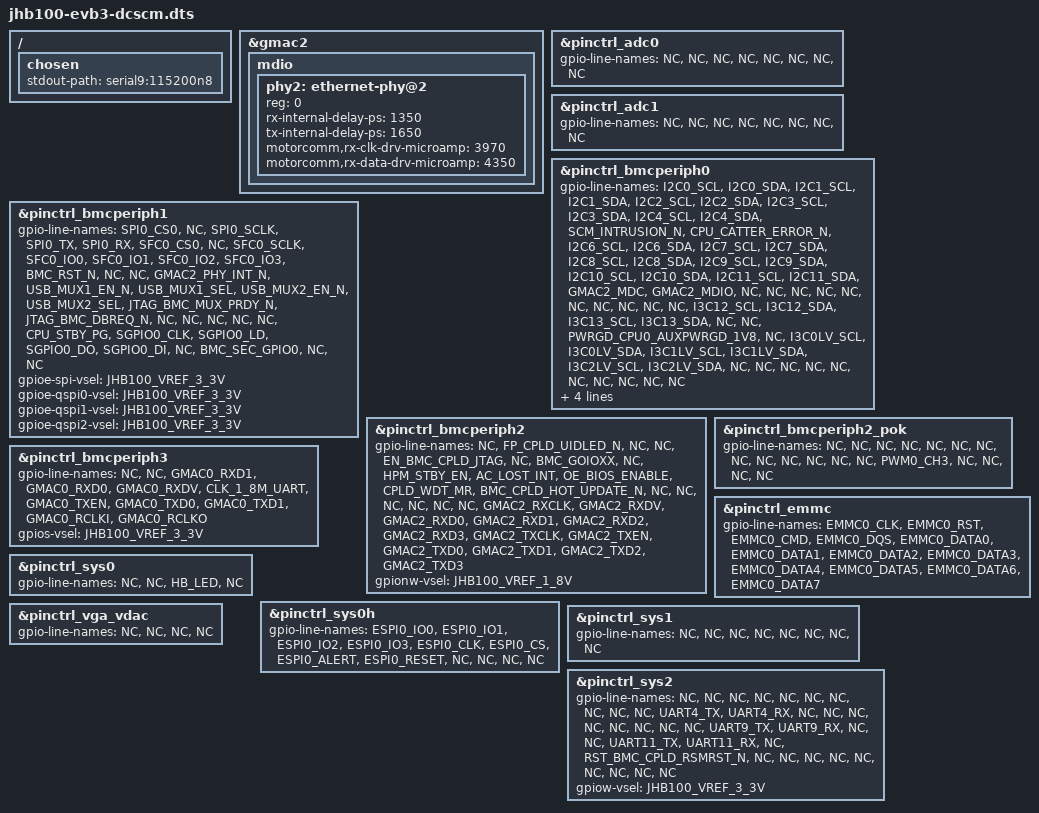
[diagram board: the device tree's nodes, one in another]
// SPDX-License-Identifier: GPL-2.0 OR MIT
/*
 * Copyright (c) 2025 StarFive Technology Co., Ltd.
 */

#include "jhb100-evb3.dtsi"
#include "jhb100-dcscm.dtsi"

/ {
	chosen {
		stdout-path = "serial9:115200n8";
	};
};

&gmac2 {
	mdio {
		phy2: ethernet-phy@2 {
			reg = <0>;
			rx-internal-delay-ps = <1350>;
			tx-internal-delay-ps = <1650>;
			motorcomm,rx-clk-drv-microamp = <3970>;
			motorcomm,rx-data-drv-microamp = <4350>;
		};
	};
};

&pinctrl_adc0 {
	gpio-line-names =
		"NC", "NC", "NC", "NC",		/* GPIOG0-3 */
		"NC", "NC", "NC", "NC";		/* GPIOG4-7 */
};

&pinctrl_adc1 {
	gpio-line-names =
		"NC", "NC", "NC", "NC",		/* GPIOH0-3 */
		"NC", "NC", "NC", "NC";		/* GPIOH4-7 */
};

&pinctrl_bmcperiph0 {
	gpio-line-names =
		"I2C0_SCL", "I2C0_SDA", "I2C1_SCL", "I2C1_SDA",			/* GPIOB0-3 */
		"I2C2_SCL", "I2C2_SDA", "I2C3_SCL", "I2C3_SDA",			/* GPIOB4-7 */
		"I2C4_SCL", "I2C4_SDA",						/* GPIOB8-9 */
		"SCM_INTRUSION_N", "CPU_CATTER_ERROR_N",			/* GPIOB10-11 */
		"I2C6_SCL", "I2C6_SDA", "I2C7_SCL", "I2C7_SDA",			/* GPIOB12-15 */
		"I2C8_SCL", "I2C8_SDA", "I2C9_SCL", "I2C9_SDA",			/* GPIOB16-19 */
		"I2C10_SCL", "I2C10_SDA", "I2C11_SCL", "I2C11_SDA",		/* GPIOB20-23 */
		"GMAC2_MDC", "GMAC2_MDIO", "NC", "NC",				/* GPIOB24-27 */
		"NC", "NC", "NC", "NC",						/* GPIOB28-31 */
		"NC", "NC", "NC", "NC",						/* GPIOB32-35 */
		"I3C12_SCL", "I3C12_SDA", "I3C13_SCL", "I3C13_SDA",		/* GPIOB36-39 */
		"NC", "NC", "PWRGD_CPU0_AUXPWRGD_1V8", "NC",			/* GPIOB40-43 */
		"I3C0LV_SCL", "I3C0LV_SDA", "I3C1LV_SCL", "I3C1LV_SDA",		/* GPIOB44-47 */
		"I3C2LV_SCL", "I3C2LV_SDA", "NC", "NC",				/* GPIOB48-51 */
		"NC", "NC", "NC", "NC",						/* GPIOB52-55 */
		"NC", "NC", "NC", "NC";						/* GPIOB56-59 */

	gpioe-i3c0-vsel = <JHB100_VREF_3_3V>; /* VREF for GPIOB8-11, 32-33 */
	gpioe-i3c1-vsel = <JHB100_VREF_3_3V>; /* VREF for GPIOB12-15, 34-35 */
	gpioe-i3c2-vsel = <JHB100_VREF_3_3V>; /* VREF for GPIOB16-23 */
	gpioe-i3c4-vsel = <JHB100_VREF_1_8V>; /* VREF for GPIOB36-43 */
};

&pinctrl_bmcperiph1 {
	gpio-line-names =
		"SPI0_CS0", "NC", "SPI0_SCLK", "SPI0_TX",		/* GPIOC0-3 */
		"SPI0_RX", "SFC0_CS0", "NC", "SFC0_SCLK",		/* GPIOC4-7 */
		"SFC0_IO0", "SFC0_IO1", "SFC0_IO2", "SFC0_IO3",		/* GPIOC8-11 */
		"BMC_RST_N", "NC", "NC", "GMAC2_PHY_INT_N",		/* GPIOC12-15 */
		"USB_MUX1_EN_N", "USB_MUX1_SEL",			/* GPIOC16-17 */
		"USB_MUX2_EN_N", "USB_MUX2_SEL",			/* GPIOC18-19 */
		"JTAG_BMC_MUX_PRDY_N", "JTAG_BMC_DBREQ_N", "NC", "NC",	/* GPIOC20-23 */
		"NC", "NC", "NC", "CPU_STBY_PG",			/* GPIOC24-27 */
		"SGPIO0_CLK", "SGPIO0_LD", "SGPIO0_DO", "SGPIO0_DI",	/* GPIOC28-31 */
		"NC", "BMC_SEC_GPIO0", "NC", "NC";			/* GPIOC32-35 */

	gpioe-spi-vsel = <JHB100_VREF_3_3V>; /* VREF for GPIOC0-4 */
	gpioe-qspi0-vsel = <JHB100_VREF_3_3V>; /* VREF for GPIOC5-11 */
	gpioe-qspi1-vsel = <JHB100_VREF_3_3V>; /* VREF for GPIOC12-19 */
	gpioe-qspi2-vsel = <JHB100_VREF_3_3V>; /* VREF for GPIOC20-27 */
};

&pinctrl_bmcperiph2 {
	gpio-line-names =
		"NC", "FP_CPLD_UIDLED_N", "NC", "NC",				/* GPIOD0-3 */
		"EN_BMC_CPLD_JTAG", "NC", "BMC_GOIOXX", "NC",			/* GPIOD4-7 */
		"HPM_STBY_EN", "AC_LOST_INT", "OE_BIOS_ENABLE", "CPLD_WDT_MR",	/* GPIOD8-11 */
		"BMC_CPLD_HOT_UPDATE_N", "NC", "NC", "NC",			/* GPIOD12-15 */
		"NC", "NC", "NC", "GMAC2_RXCLK",				/* GPIOD16-19 */
		"GMAC2_RXDV", "GMAC2_RXD0", "GMAC2_RXD1", "GMAC2_RXD2",		/* GPIOD20-23 */
		"GMAC2_RXD3", "GMAC2_TXCLK", "GMAC2_TXEN", "GMAC2_TXD0",	/* GPIOD24-27 */
		"GMAC2_TXD1", "GMAC2_TXD2", "GMAC2_TXD3";			/* GPIOD28-30 */

	gpionw-vsel = <JHB100_VREF_1_8V>; /* VREF for GPIOD19-30 */
};

&pinctrl_bmcperiph2_pok {
	gpio-line-names =
		"NC", "NC", "NC", "NC",			/* GPIOD31-34 */
		"NC", "NC", "NC", "NC",			/* GPIOD35-38 */
		"NC", "NC", "NC", "NC",			/* GPIOD39-42 */
		"NC", "PWM0_CH3", "NC", "NC",		/* GPIOD43-46 */
		"NC", "NC";				/* GPIOD47-48 */
};

&pinctrl_bmcperiph3 {
	gpio-line-names =
		"NC", "NC", "GMAC0_RXD1", "GMAC0_RXD0",				/* GPIOE0-3 */
		"GMAC0_RXDV", "CLK_1_8M_UART", "GMAC0_TXEN", "GMAC0_TXD0",	/* GPIOE4-7 */
		"GMAC0_TXD1", "GMAC0_RCLKI", "GMAC0_RCLKO";			/* GPIOE8-11 */

	gpios-vsel = <JHB100_VREF_3_3V>; /* VREF for GPIOE0-10 */
};

&pinctrl_emmc {
	gpio-line-names =
		"EMMC0_CLK", "EMMC0_RST", "EMMC0_CMD", "EMMC0_DQS",		/* GPIOF0-3 */
		"EMMC0_DATA0", "EMMC0_DATA1", "EMMC0_DATA2", "EMMC0_DATA3",	/* GPIOF4-7 */
		"EMMC0_DATA4", "EMMC0_DATA5", "EMMC0_DATA6", "EMMC0_DATA7";	/* GPIOF8-11 */
};

&pinctrl_sys0 {
	gpio-line-names =
		"NC", "NC", "HB_LED", "NC";		/* GPIOA0-3 */
};

&pinctrl_sys0h {
	gpio-line-names =
		"ESPI0_IO0", "ESPI0_IO1", "ESPI0_IO2", "ESPI0_IO3",		/* GPIOA4-7 */
		"ESPI0_CLK", "ESPI0_CS", "ESPI0_ALERT", "ESPI0_RESET",		/* GPIOA8-11 */
		"NC", "NC", "NC", "NC";						/* GPIOA12-15 */
};

&pinctrl_sys1 {
	gpio-line-names =
		"NC", "NC", "NC", "NC",		/* GPIOA16-19 */
		"NC", "NC", "NC", "NC";		/* GPIOA20-23 */
};

&pinctrl_sys2 {
	gpio-line-names =
		"NC", "NC", "NC", "NC",						/* GPIOA24-27 */
		"NC", "NC", "NC", "NC",						/* GPIOA28-31 */
		"NC", "NC", "UART4_TX", "UART4_RX",				/* GPIOA32-35 */
		"NC", "NC", "NC", "NC",						/* GPIOA36-39 */
		"NC", "NC", "NC", "NC",						/* GPIOA40-43 */
		"UART9_TX", "UART9_RX", "NC", "NC",				/* GPIOA44-47 */
		"UART11_TX", "UART11_RX", "NC", "RST_BMC_CPLD_RSMRST_N",	/* GPIOA48-51 */
		"NC", "NC", "NC", "NC",						/* GPIOA52-55 */
		"NC", "NC", "NC", "NC",						/* GPIOA56-59 */
		"NC";								/* GPIOA60 */

	gpiow-vsel = <JHB100_VREF_3_3V>; /* VREF for GPIOA36-43 */
};

&pinctrl_vga_vdac {
	gpio-line-names =
		"NC", "NC", "NC", "NC";		/* GPIOI0-3 */
};
